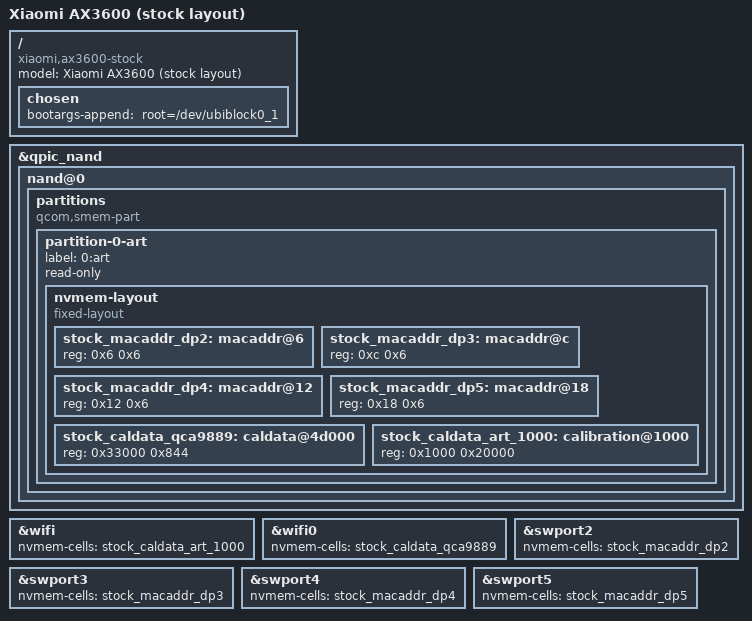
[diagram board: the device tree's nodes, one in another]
// SPDX-License-Identifier: GPL-2.0-or-later OR MIT
/*
 * Copyright (c) 2020, 2021, 2022, 2023, 2024, 2025
 * Chukun Pan
 */

#include "ipq8071-ax3600.dts"

/ {
	model = "Xiaomi AX3600 (stock layout)";
	compatible = "xiaomi,ax3600-stock", "qcom,ipq8074";

	chosen {
		bootargs-append = " root=/dev/ubiblock0_1";
	};
};

&qpic_nand {
	/delete-node/ partitions;

	nand@0 {
		/delete-node/ partitions;

		partitions {
			compatible = "qcom,smem-part";

			partition-0-art {
				label = "0:art";
				read-only;

				nvmem-layout {
					compatible = "fixed-layout";
					#address-cells = <1>;
					#size-cells = <1>;

					/*
					 * Use distinct "stock_" labels. The base DTS references
					 * labels defined inside the fixed-partitions node that is
					 * deleted above; reusing the same names leaves those
					 * references bound to deleted nodes (dangling phandles),
					 * so calibration/MAC data cannot be read and all radios
					 * fail to probe. All consumers are rebound below.
					 */
					stock_macaddr_dp2: macaddr@6 {
						reg = <0x6 0x6>;
					};

					stock_macaddr_dp3: macaddr@c {
						reg = <0xc 0x6>;
					};

					stock_macaddr_dp4: macaddr@12 {
						reg = <0x12 0x6>;
					};

					stock_macaddr_dp5: macaddr@18 {
						reg = <0x18 0x6>;
					};

					stock_caldata_qca9889: caldata@4d000 {
						reg = <0x33000 0x844>;
					};

					stock_caldata_art_1000: calibration@1000 {
						reg = <0x1000 0x20000>;
					};
				};
			};
		};
	};
};

/* Rebind NVMEM consumers to the stock-layout cells above. */
&wifi {
	nvmem-cells = <&stock_caldata_art_1000>;
};

&wifi0 {
	nvmem-cells = <&stock_caldata_qca9889>;
};

&swport2 {
	nvmem-cells = <&stock_macaddr_dp2>;
};

&swport3 {
	nvmem-cells = <&stock_macaddr_dp3>;
};

&swport4 {
	nvmem-cells = <&stock_macaddr_dp4>;
};

&swport5 {
	nvmem-cells = <&stock_macaddr_dp5>;
};
